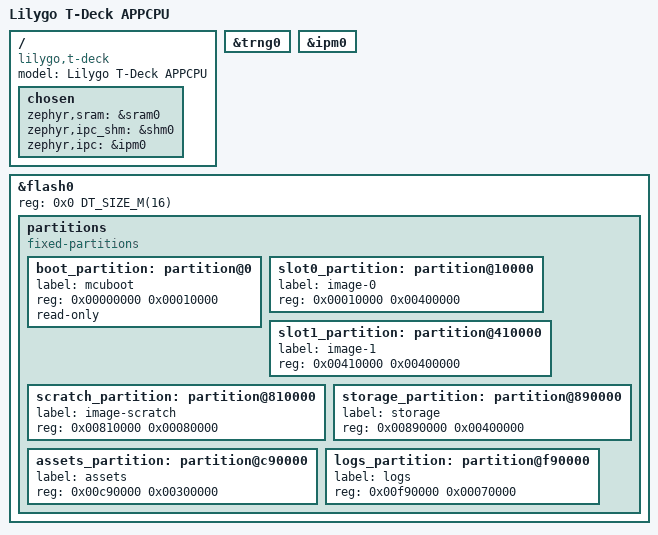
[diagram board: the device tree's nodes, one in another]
/* SPDX-License-Identifier: GPL-3.0-or-later */
/* SPDX-FileCopyrightText: The contributors to the LICHEN project */

 /dts-v1/;

#include <espressif/esp32s3/esp32s3_appcpu.dtsi>

/ {
	model = "Lilygo T-Deck APPCPU";
	compatible = "lilygo,t-deck";

	chosen {
		zephyr,sram = &sram0;
		zephyr,ipc_shm = &shm0;
		zephyr,ipc = &ipm0;
	};
};

&trng0 { status = "okay"; };
&ipm0 { status = "okay"; };

&flash0 {
	reg = <0x0 DT_SIZE_M(16)>;
	status = "okay";
	partitions {
		compatible = "fixed-partitions";
		#address-cells = <1>;
		#size-cells = <1>;

		boot_partition: partition@0 {
			label = "mcuboot";
			reg = <0x00000000 0x00010000>;
			read-only;
		};
		slot0_partition: partition@10000 {
			label = "image-0";
			reg = <0x00010000 0x00400000>;
		};
		slot1_partition: partition@410000 {
			label = "image-1";
			reg = <0x00410000 0x00400000>;
		};
		scratch_partition: partition@810000 {
			label = "image-scratch";
			reg = <0x00810000 0x00080000>;
		};
		storage_partition: partition@890000 {
			label = "storage";
			reg = <0x00890000 0x00400000>;
		};
		assets_partition: partition@c90000 {
			label = "assets";
			reg = <0x00c90000 0x00300000>;
		};
		logs_partition: partition@f90000 {
			label = "logs";
			reg = <0x00f90000 0x00070000>;
		};
	};
};

